# TOP_CTRL register map
Vendor: Texas Instruments
Peripheral module from a debugger description file (folder awr2x44p).
Registers are 32-bit, read-only, no defined reset value unless marked. A register's access mark holds for its fields unless they carry their own. Offsets are as the file gives them; lines under a group give offsets from that group; [hi:lo] are bit positions; {n}, {i} and the like mark numbered series; 'fields as' and 'values as' point back to an identical list; <NAME> marks a mode.

## TOP_CTRL
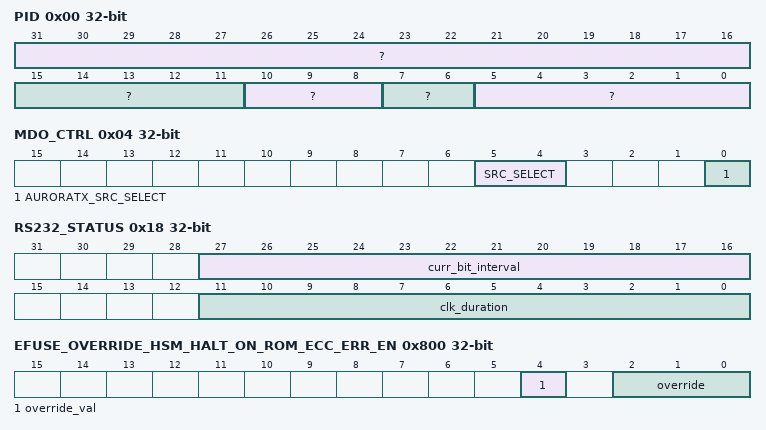
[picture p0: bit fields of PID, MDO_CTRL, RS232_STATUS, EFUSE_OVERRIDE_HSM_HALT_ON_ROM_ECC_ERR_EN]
0x00 PID
  [31:16] ?, [15:11] ?, [10:8] ?, [7:6] ?, [5:0] ?
0x04 MDO_CTRL rw
  [5:4] SRC_SELECT — Select the source IP of LVDS Data 0: Aurora full data on LVDS 1: CBUFF on LVDS 2: Aurora bit-clk ,frame clk and 2 data support. 3: Aurora 1bit clk and 2 data support for LOP package
  [0] AURORATX_SRC_SELECT — Select the TPIU source to TOP_AURORATX IP 0:Measurement Data 1: Trace Data
0x08 PROBE_BUS_SEL0 rw
  [31:0] sel — Probe Bus 0 Mux Select
0x0C PROBE_BUS_SEL1 rw
  [31:0] sel — Probe Bus 1 Mux Select
0x10 RS232_SLEEP_CLK_DIV rw
  [31:0] div_val — The Divider value for RS232 sleep clock generation from RCclk
0x14 RS232_SLEEP_CLK_DIV_by2 rw
  [31:0] div_val — The Dividerby2 value for RS232 sleep clock generation from RCclk. This decides the duty cycle of sleep clock.
0x18 RS232_STATUS
  [27:16] curr_bit_interval — Current RS232 bit interval being used
  [11:0] clk_duration — Number of vbusp clocks measured in one sleep clock frequency
{0x200+4i} EFUSE_DIEID{i} (i=0..3)
  [31:0] val — EFUSE DieID[{32i+31}:{32i}]
{0x210+4i} EFUSE_UID{i} (i=0..2)
  [31:0] val — EFUSE UID[{32i+31}:{32i}]
0x21C EFUSE_UID3
  [23:0] val — EFUSE UID[120:96]
0x220 PREVIOUS_NAME
  [15:0] val — EFUSE Device Type
0x224 EFUSE_FROM0_CHECKSUM
  [31:0] val — 32 bit FROM0 Checksum
0x228 EFUSE_ROM_SEQ_UPDATE0
  [31:0] val — EFUSE ROM Seq Update [31:0]
0x22C EFUSE_ROM_SEQ_UPDATE1
  [31:0] val — EFUSE ROM Seq Update[63:32]
0x230 EFUSE_ROM_SEQ_UPDATE2
  [31:0] val — EFUSE ROM Seq Update[95:64]
0x234 EFUSE_ROM_SEQ_UPDATE3
  [31:0] val — EFUSE ROM Seq Update[127:96
{0x228+4i} EFUSE_ROM_SEQ_UPDATE{i} (i=4..8)
  [31:0] val — EFUSE ROM Seq Update[{32i+31}:{32i}]
{0x30C+4i} EFUSE0_ROW_{i} (i=61..63)
  [25:0] EFUSE0_ROW_{i} — Captures the EFUSE Value. Refer to EFUSE Mapping XLS for more details
{0x3F8+4i} EFUSE1_ROW_{i} (i=5..43)
  [25:0] EFUSE1_ROW_{i} — Captures the EFUSE Value. Refer to EFUSE Mapping XLS for more details
0x800 EFUSE_OVERRIDE_HSM_HALT_ON_ROM_ECC_ERR_EN rw
  [4] override_val — Override MMR value
  [2:0] override — Override EFUSE Value with SW Value Write 3'b000 : EFUSE Value Write 3'b111 : MMR Value
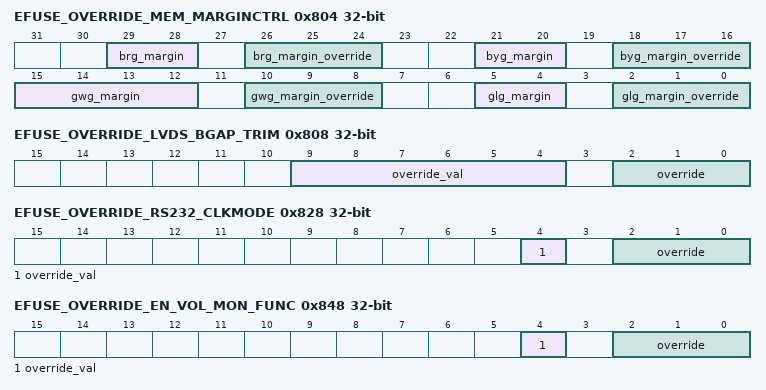
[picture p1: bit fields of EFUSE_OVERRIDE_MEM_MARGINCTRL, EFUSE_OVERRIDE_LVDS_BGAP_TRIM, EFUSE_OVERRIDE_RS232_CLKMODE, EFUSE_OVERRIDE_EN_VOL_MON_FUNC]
0x804 EFUSE_OVERRIDE_MEM_MARGINCTRL rw
  [29:28] brg_margin — Override MMR value
  [26:24] brg_margin_override — Override EFUSE Value with SW Value Write 3'b000 : EFUSE Value Write 3'b111 : MMR Value
  [21:20] byg_margin — Override MMR value
  [18:16] byg_margin_override — Override EFUSE Value with SW Value Write 3'b000 : EFUSE Value Write 3'b111 : MMR Value
  [15:12] gwg_margin — Override MMR value
  [10:8] gwg_margin_override — Override EFUSE Value with SW Value Write 3'b000 : EFUSE Value Write 3'b111 : MMR Value
  [5:4] glg_margin — Override MMR value
  [2:0] glg_margin_override — Override EFUSE Value with SW Value Write 3'b000 : EFUSE Value Write 3'b111 : MMR Value
0x808 EFUSE_OVERRIDE_LVDS_BGAP_TRIM rw
  [9:4] override_val — Override MMR value
  [2:0] override — Override EFUSE Value with SW Value Write 3'b000 : EFUSE Value Write 3'b111 : MMR Value
0x80C EFUSE_OVERRIDE_XTAL_STABLIZATION_WAIT rw
  [2:0] override — Override EFUSE Value with SW Value Write 3'b000 : EFUSE Value Write 3'b111 : MMR Value . Refer to the ANAREG in TOP_RCM for the override value
0x810 EFUSE_OVERRIDE_SLICER_BIAS_RTRIM rw
  fields as EFUSE_OVERRIDE_XTAL_STABLIZATION_WAIT
0x814 EFUSE_OVERRIDE_XO_OUTPUT_DRIVE rw
  fields as EFUSE_OVERRIDE_XTAL_STABLIZATION_WAIT
0x818 EFUSE_OVERRIDE_RCOSC_TRIM_CODE rw
  fields as EFUSE_OVERRIDE_XTAL_STABLIZATION_WAIT
0x81C EFUSE_OVERRIDE_IP1_BG1_RTRIM rw
  [2:0] override — Override EFUSE Value with SW Value Write 3'b000 : EFUSE Value Write 3'b111 : MMR Value. Refer to the ANAREG in TOP_RCM for the override value
0x820 EFUSE_OVERRIDE_IP1_BG1_SLOPE rw
  fields as EFUSE_OVERRIDE_IP1_BG1_RTRIM
0x824 EFUSE_OVERRIDE_IP1_BG1_MAG rw
  fields as EFUSE_OVERRIDE_IP1_BG1_RTRIM
0x828 EFUSE_OVERRIDE_RS232_CLKMODE rw
  [4] override_val — Override value for RS232 Clock Mode 0 : Autobaud 1 : Fixed Interval
  [2:0] override — Override EFUSE Value with SW Value Write 3'b000 : EFUSE Value Write 3'b111 : MMR Value.
0x82C EFUSE_OVERRIDE_VMON_VDD_OV_UV_TRIM rw
  fields as EFUSE_OVERRIDE_IP1_BG1_RTRIM
0x830 EFUSE_OVERRIDE_VMON_VDDS_3P3_UV_TRIM rw
  fields as EFUSE_OVERRIDE_IP1_BG1_RTRIM
0x834 EFUSE_OVERRIDE_VMON_VDDA_OSC_TRIM rw
  fields as EFUSE_OVERRIDE_IP1_BG1_RTRIM
0x838 EFUSE_OVERRIDE_VDD_VT_DET rw
  fields as EFUSE_OVERRIDE_IP1_BG1_RTRIM
0x83C EFUSE_OVERRIDE_MASK_CPU_CLK_OUT_CTRL_LOWV_VAL rw
  fields as EFUSE_OVERRIDE_IP1_BG1_RTRIM
0x840 EFUSE_OVERRIDE_MASK_CPU_CLK_OUT_CTRL_LOWV_SEL rw
  fields as EFUSE_OVERRIDE_IP1_BG1_RTRIM
0x844 EFUSE_OVERRIDE_EN_VOL_MON_FUNC rw
  fields as EFUSE_OVERRIDE_IP1_BG1_RTRIM
0x848 EFUSE_OVERRIDE_EN_VOL_MON_FUNC rw
  [4] override_val — Override value for Hold Buffer Enable 0 : Disabled 1 : Enabled
  [2:0] override — Override EFUSE Value with SW Value Write 3'b000 : EFUSE Value Write 3'b111 : MMR Value.
0x84C EFUSE_OVERRIDE_SPARE_ANA rw
  fields as EFUSE_OVERRIDE_IP1_BG1_RTRIM
0x850 EFUSE_OVERRIDE_SLICER_DLY_DISABLE rw
  fields as EFUSE_OVERRIDE_IP1_BG1_RTRIM
{0xFD0+4i} HW_SPARE_RW{i} rw (i=0..3)
  [31:0] hw_spare_rw{i} — Reserved for HW R&D
{0xFE0+4i} HW_SPARE_RO{i} (i=0..3)
  [31:0] hw_spare_ro{i} — Reserved for HW R&D
0xFF0 HW_SPARE_WPH rw
  [31:0] hw_spare_wph — write pulse bit field:Reserved for HW R&D
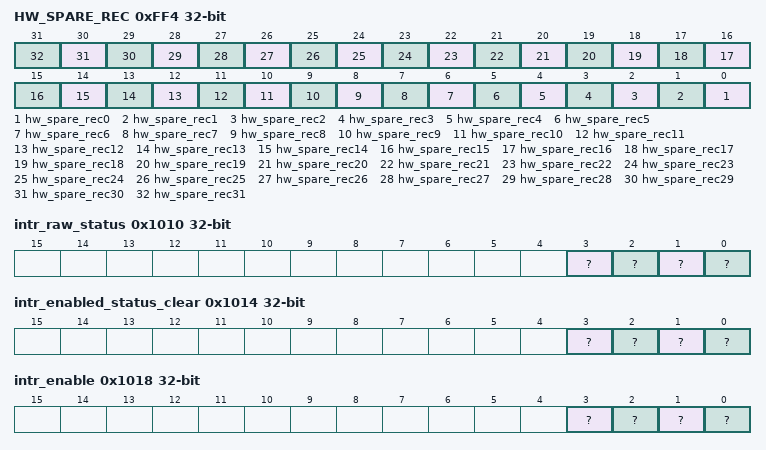
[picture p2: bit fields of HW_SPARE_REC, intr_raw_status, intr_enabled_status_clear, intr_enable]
0xFF4 HW_SPARE_REC rw
  [n] hw_spare_rec{n} (n=0..31) — Rising Edge Capture reg (write 1 to clear): Reserved for HW R&D
0x1008 LOCK0_KICK0 rw — - KICK0 component
  [31:0] ?
0x100C LOCK0_KICK1 rw — - KICK1 component
  [31:0] ?
0x1010 intr_raw_status rw — Interrupt Raw Status/Set Register
  [3] ? — Proxy0 access violation error. Raw status is read. Write a 1 to set the status. Writing a 0 has no effect.
  [2] ? — Kick access violation error. Raw status is read. Write a 1 to set the status. Writing a 0 has no effect.
  [1] ? — Addressing violation error. Raw status is read. Write a 1 to set the status. Writing a 0 has no effect.
  [0] ? — Protection violation error. Raw status is read. Write a 1 to set the status. Writing a 0 has no effect.
0x1014 intr_enabled_status_clear rw — Interrupt Enabled Status/Clear register
  [3] ? — Proxy0 access violation error. Enabled status is read. Write a 1 to clear the status. Writing a 0 has no effect.
  [2] ? — Kick access violation error. Enabled status is read. Write a 1 to clear the status. Writing a 0 has no effect.
  [1] ? — Addressing violation error. Enabled status is read. Write a 1 to clear the status. Writing a 0 has no effect.
  [0] ? — Protection violation error. Enabled status is read. Write a 1 to clear the status. Writing a 0 has no effect.
0x1018 intr_enable rw — Interrupt Enable register
  [3] ? — Proxy0 access violation error enable. Write a 1 to set the enable. Writing a 0 has no effect.
  [2] ? — Kick access violation error enable. Write a 1 to set the enable. Writing a 0 has no effect.
  [1] ? — Addressing violation error enable. Write a 1 to set the enable. Writing a 0 has no effect.
  [0] ? — Protection violation error enable. Write a 1 to set the enable. Writing a 0 has no effect.
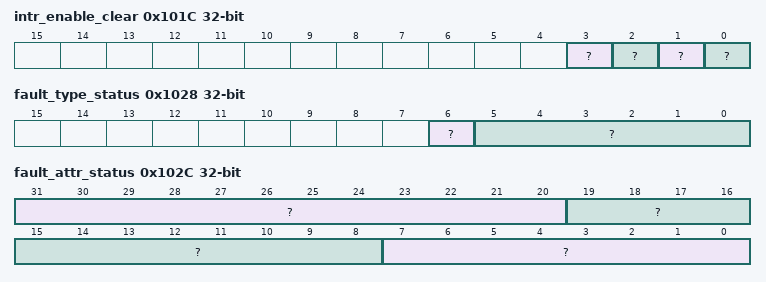
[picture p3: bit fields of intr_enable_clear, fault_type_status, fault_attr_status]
0x101C intr_enable_clear rw — Interrupt Enable Clear register
  [3] ? — Proxy0 access violation error enable clear. Write a 1 to clear the enable. Writing a 0 has no effect.
  [2] ? — Kick access violation error enable clear. Write a 1 to clear the enable. Writing a 0 has no effect.
  [1] ? — Addressing violation error enable clear. Write a 1 to clear the enable. Writing a 0 has no effect.
  [0] ? — Protection violation error enable clear. Write a 1 to clear the enable. Writing a 0 has no effect.
0x1020 eoi rw
  [7:0] ? — EOI vector value. Write this with interrupt distribution value in the chip.
0x1024 fault_address
  [31:0] ? — Fault Address.
0x1028 fault_type_status
  [6] ? — Non-secure access.
  [5:0] ? — Fault Type 10_0000 = Supervisor read fault - priv = 1 dir = 1 dtype != 1 01_0000 = Supervisor write fault - priv = 1 dir = 0 00_1000 = Supervisor execute fault - priv = 1 dir = 1 dtype = 1 00_0100 = User read fault - priv = 0 dir = 1 dtype = 1 00_0010 = User write fault - priv = 0 dir = 0 00_0001 = User execute fault - priv = 0 dir = 1 dtype = 1 00_0000 = No fault
0x102C fault_attr_status — Fault Attribute Status register
  [31:20] ? — XID.
  [19:8] ? — Route ID.
  [7:0] ? — Privilege ID.
0x1030 fault_clear wo
  [0] ? — Fault clear. Writing a 1 clears the current fault. Writing a 0 has no effect.
